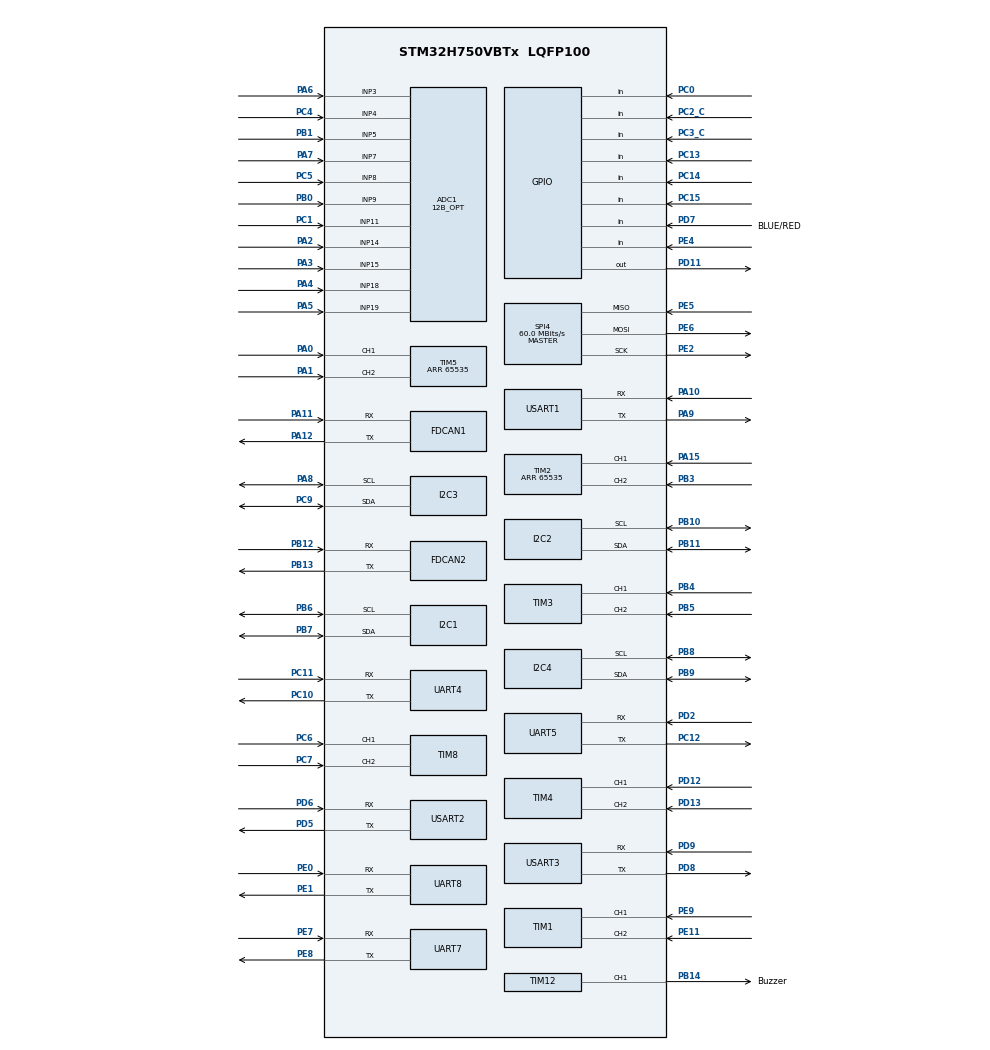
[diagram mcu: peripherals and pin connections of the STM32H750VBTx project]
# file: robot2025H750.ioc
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ADC1.Channel-0\#ChannelRegularConversion=ADC_CHANNEL_11
ADC1.Channel-1\#ChannelRegularConversion=ADC_CHANNEL_14
ADC1.Channel-10\#ChannelRegularConversion=ADC_CHANNEL_5
ADC1.Channel-2\#ChannelRegularConversion=ADC_CHANNEL_15
ADC1.Channel-3\#ChannelRegularConversion=ADC_CHANNEL_18
ADC1.Channel-4\#ChannelRegularConversion=ADC_CHANNEL_19
ADC1.Channel-5\#ChannelRegularConversion=ADC_CHANNEL_3
ADC1.Channel-6\#ChannelRegularConversion=ADC_CHANNEL_7
ADC1.Channel-7\#ChannelRegularConversion=ADC_CHANNEL_4
ADC1.Channel-8\#ChannelRegularConversion=ADC_CHANNEL_8
ADC1.Channel-9\#ChannelRegularConversion=ADC_CHANNEL_9
ADC1.ClockPrescaler=ADC_CLOCK_ASYNC_DIV4
ADC1.ContinuousConvMode=ENABLE
ADC1.ConversionDataManagement=ADC_CONVERSIONDATA_DMA_CIRCULAR
ADC1.ExternalTrigConv=ADC_SOFTWARE_START
ADC1.LowPowerAutoWait=ENABLE
ADC1.NbrOfConversion=11
ADC1.NbrOfConversionFlag=1
ADC1.OffsetNumber-0\#ChannelRegularConversion=ADC_OFFSET_NONE
ADC1.OffsetNumber-1\#ChannelRegularConversion=ADC_OFFSET_NONE
ADC1.OffsetNumber-10\#ChannelRegularConversion=ADC_OFFSET_NONE
ADC1.OffsetNumber-2\#ChannelRegularConversion=ADC_OFFSET_NONE
ADC1.OffsetNumber-3\#ChannelRegularConversion=ADC_OFFSET_NONE
ADC1.OffsetNumber-4\#ChannelRegularConversion=ADC_OFFSET_NONE
ADC1.OffsetNumber-5\#ChannelRegularConversion=ADC_OFFSET_NONE
ADC1.OffsetNumber-6\#ChannelRegularConversion=ADC_OFFSET_NONE
ADC1.OffsetNumber-7\#ChannelRegularConversion=ADC_OFFSET_NONE
ADC1.OffsetNumber-8\#ChannelRegularConversion=ADC_OFFSET_NONE
ADC1.OffsetNumber-9\#ChannelRegularConversion=ADC_OFFSET_NONE
ADC1.OffsetSignedSaturation-0\#ChannelRegularConversion=DISABLE
ADC1.OffsetSignedSaturation-1\#ChannelRegularConversion=DISABLE
ADC1.Rank-0\#ChannelRegularConversion=1
ADC1.Rank-1\#ChannelRegularConversion=2
ADC1.Rank-10\#ChannelRegularConversion=11
ADC1.Rank-2\#ChannelRegularConversion=3
ADC1.Rank-3\#ChannelRegularConversion=4
ADC1.Rank-4\#ChannelRegularConversion=5
ADC1.Rank-5\#ChannelRegularConversion=6
ADC1.Rank-6\#ChannelRegularConversion=7
ADC1.Rank-7\#ChannelRegularConversion=8
ADC1.Rank-8\#ChannelRegularConversion=9
ADC1.Rank-9\#ChannelRegularConversion=10
ADC1.Resolution=ADC_RESOLUTION_12B_OPT
ADC1.SamplingTime-0\#ChannelRegularConversion=ADC_SAMPLETIME_64CYCLES_5
ADC1.SamplingTime-1\#ChannelRegularConversion=ADC_SAMPLETIME_64CYCLES_5
ADC1.SamplingTime-10\#ChannelRegularConversion=ADC_SAMPLETIME_64CYCLES_5
ADC1.SamplingTime-2\#ChannelRegularConversion=ADC_SAMPLETIME_64CYCLES_5
ADC1.SamplingTime-3\#ChannelRegularConversion=ADC_SAMPLETIME_64CYCLES_5
ADC1.SamplingTime-4\#ChannelRegularConversion=ADC_SAMPLETIME_64CYCLES_5
ADC1.SamplingTime-5\#ChannelRegularConversion=ADC_SAMPLETIME_64CYCLES_5
ADC1.SamplingTime-6\#ChannelRegularConversion=ADC_SAMPLETIME_64CYCLES_5
ADC1.SamplingTime-7\#ChannelRegularConversion=ADC_SAMPLETIME_810CYCLES_5
ADC1.SamplingTime-8\#ChannelRegularConversion=ADC_SAMPLETIME_64CYCLES_5
ADC1.SamplingTime-9\#ChannelRegularConversion=ADC_SAMPLETIME_64CYCLES_5
ADC1.master=1
CORTEX_M7.default_mode_Activation=1
Dma.ADC1.0.Direction=DMA_PERIPH_TO_MEMORY
Dma.ADC1.0.EventEnable=DISABLE
Dma.ADC1.0.FIFOMode=DMA_FIFOMODE_DISABLE
Dma.ADC1.0.Instance=DMA1_Stream0
Dma.ADC1.0.MemDataAlignment=DMA_MDATAALIGN_HALFWORD
Dma.ADC1.0.MemInc=DMA_MINC_ENABLE
Dma.ADC1.0.Mode=DMA_CIRCULAR
Dma.ADC1.0.PeriphDataAlignment=DMA_PDATAALIGN_HALFWORD
Dma.ADC1.0.PeriphInc=DMA_PINC_DISABLE
Dma.ADC1.0.Polarity=HAL_DMAMUX_REQ_GEN_RISING
Dma.ADC1.0.Priority=DMA_PRIORITY_LOW
Dma.ADC1.0.RequestNumber=1
Dma.ADC1.0.SignalID=NONE
Dma.ADC1.0.SyncEnable=DISABLE
Dma.ADC1.0.SyncPolarity=HAL_DMAMUX_SYNC_NO_EVENT
Dma.ADC1.0.SyncRequestNumber=1
Dma.ADC1.0.SyncSignalID=NONE
Dma.Request0=ADC1
Dma.Request1=UART4_RX
Dma.Request2=USART3_RX
Dma.Request3=UART5_RX
Dma.Request4=USART1_TX
Dma.UART4_RX.1.Direction=DMA_PERIPH_TO_MEMORY
Dma.UART4_RX.1.EventEnable=DISABLE
Dma.UART4_RX.1.FIFOMode=DMA_FIFOMODE_DISABLE
Dma.UART4_RX.1.Instance=DMA1_Stream2
Dma.UART4_RX.1.MemDataAlignment=DMA_MDATAALIGN_BYTE
Dma.UART4_RX.1.MemInc=DMA_MINC_ENABLE
Dma.UART4_RX.1.Mode=DMA_CIRCULAR
Dma.UART4_RX.1.PeriphDataAlignment=DMA_PDATAALIGN_BYTE
Dma.UART4_RX.1.PeriphInc=DMA_PINC_DISABLE
Dma.UART4_RX.1.Polarity=HAL_DMAMUX_REQ_GEN_RISING
Dma.UART4_RX.1.Priority=DMA_PRIORITY_LOW
Dma.UART4_RX.1.RequestNumber=1
Dma.UART4_RX.1.SignalID=NONE
Dma.UART4_RX.1.SyncEnable=DISABLE
Dma.UART4_RX.1.SyncPolarity=HAL_DMAMUX_SYNC_NO_EVENT
Dma.UART4_RX.1.SyncRequestNumber=1
Dma.UART4_RX.1.SyncSignalID=NONE
Dma.UART5_RX.3.Direction=DMA_PERIPH_TO_MEMORY
Dma.UART5_RX.3.EventEnable=DISABLE
Dma.UART5_RX.3.FIFOMode=DMA_FIFOMODE_ENABLE
Dma.UART5_RX.3.FIFOThreshold=DMA_FIFO_THRESHOLD_HALFFULL
Dma.UART5_RX.3.Instance=DMA1_Stream4
Dma.UART5_RX.3.MemBurst=DMA_MBURST_SINGLE
Dma.UART5_RX.3.MemDataAlignment=DMA_MDATAALIGN_BYTE
Dma.UART5_RX.3.MemInc=DMA_MINC_ENABLE
Dma.UART5_RX.3.Mode=DMA_CIRCULAR
Dma.UART5_RX.3.PeriphBurst=DMA_PBURST_SINGLE
Dma.UART5_RX.3.PeriphDataAlignment=DMA_PDATAALIGN_BYTE
Dma.UART5_RX.3.PeriphInc=DMA_PINC_DISABLE
Dma.UART5_RX.3.Polarity=HAL_DMAMUX_REQ_GEN_RISING
Dma.UART5_RX.3.Priority=DMA_PRIORITY_LOW
Dma.UART5_RX.3.RequestNumber=1
Dma.UART5_RX.3.SignalID=NONE
Dma.UART5_RX.3.SyncEnable=DISABLE
Dma.UART5_RX.3.SyncPolarity=HAL_DMAMUX_SYNC_NO_EVENT
Dma.UART5_RX.3.SyncRequestNumber=1
Dma.UART5_RX.3.SyncSignalID=NONE
Dma.USART1_TX.4.Direction=DMA_MEMORY_TO_PERIPH
Dma.USART1_TX.4.EventEnable=DISABLE
Dma.USART1_TX.4.FIFOMode=DMA_FIFOMODE_ENABLE
Dma.USART1_TX.4.FIFOThreshold=DMA_FIFO_THRESHOLD_HALFFULL
Dma.USART1_TX.4.Instance=DMA1_Stream1
Dma.USART1_TX.4.MemBurst=DMA_MBURST_SINGLE
Dma.USART1_TX.4.MemDataAlignment=DMA_MDATAALIGN_BYTE
Dma.USART1_TX.4.MemInc=DMA_MINC_ENABLE
Dma.USART1_TX.4.Mode=DMA_CIRCULAR
Dma.USART1_TX.4.PeriphBurst=DMA_PBURST_SINGLE
Dma.USART1_TX.4.PeriphDataAlignment=DMA_PDATAALIGN_BYTE
Dma.USART1_TX.4.PeriphInc=DMA_PINC_DISABLE
Dma.USART1_TX.4.Polarity=HAL_DMAMUX_REQ_GEN_RISING
Dma.USART1_TX.4.Priority=DMA_PRIORITY_LOW
Dma.USART1_TX.4.RequestNumber=1
Dma.USART1_TX.4.SignalID=NONE
Dma.USART1_TX.4.SyncEnable=DISABLE
Dma.USART1_TX.4.SyncPolarity=HAL_DMAMUX_SYNC_NO_EVENT
Dma.USART1_TX.4.SyncRequestNumber=1
Dma.USART1_TX.4.SyncSignalID=NONE
Dma.USART3_RX.2.Direction=DMA_PERIPH_TO_MEMORY
Dma.USART3_RX.2.EventEnable=DISABLE
Dma.USART3_RX.2.FIFOMode=DMA_FIFOMODE_ENABLE
Dma.USART3_RX.2.FIFOThreshold=DMA_FIFO_THRESHOLD_HALFFULL
Dma.USART3_RX.2.Instance=DMA1_Stream3
Dma.USART3_RX.2.MemBurst=DMA_MBURST_SINGLE
Dma.USART3_RX.2.MemDataAlignment=DMA_MDATAALIGN_BYTE
Dma.USART3_RX.2.MemInc=DMA_MINC_ENABLE
Dma.USART3_RX.2.Mode=DMA_CIRCULAR
Dma.USART3_RX.2.PeriphBurst=DMA_PBURST_SINGLE
Dma.USART3_RX.2.PeriphDataAlignment=DMA_PDATAALIGN_BYTE
Dma.USART3_RX.2.PeriphInc=DMA_PINC_DISABLE
Dma.USART3_RX.2.Polarity=HAL_DMAMUX_REQ_GEN_RISING
Dma.USART3_RX.2.Priority=DMA_PRIORITY_LOW
Dma.USART3_RX.2.RequestNumber=1
Dma.USART3_RX.2.SignalID=NONE
Dma.USART3_RX.2.SyncEnable=DISABLE
Dma.USART3_RX.2.SyncPolarity=HAL_DMAMUX_SYNC_NO_EVENT
Dma.USART3_RX.2.SyncRequestNumber=1
Dma.USART3_RX.2.SyncSignalID=NONE
FDCAN1.CalculateBaudRateNominal=1499999
FDCAN1.CalculateTimeBitNominal=666
FDCAN1.CalculateTimeQuantumNominal=133.33333333333334
FDCAN2.CalculateBaudRateNominal=1499999
FDCAN2.CalculateTimeBitNominal=666
FDCAN2.CalculateTimeQuantumNominal=133.33333333333334
FREERTOS.Tasks01=mainTask,24,128,StartMainTask,Default,NULL,Dynamic,NULL,NULL;sensorTask02,40,128,StartSensorTask02,Default,NULL,Dynamic,NULL,NULL;swerveTask03,41,128,StartSwerveTask03,Default,NULL,Dynamic,NULL,NULL;ADCTask04,39,128,StartADCTask04,Default,NULL,Dynamic,NULL,NULL;LCDTask05,8,128,StartLCDTask05,Default,NULL,Dynamic,NULL,NULL
I2C1.Timing=0x307075B1
I2C2.Timing=0x307075B1
I2C3.Timing=0x307075B1
I2C4.Timing=0x307075B1
Mcu.Family=STM32H7
Mcu.Name=STM32H750VBTx
Mcu.Package=LQFP100
NVIC.DMA1_Stream2_IRQn=true\:5\:0\:false\:false\:true\:true\:true\:true\:true
NVIC.DMA1_Stream3_IRQn=true\:5\:0\:false\:false\:true\:true\:true\:true\:true
NVIC.DMA1_Stream4_IRQn=true\:5\:0\:false\:false\:true\:true\:true\:true\:true
NVIC.PriorityGroup=NVIC_PRIORITYGROUP_4
NVIC.TIM1_UP_IRQn=true\:5\:0\:false\:false\:true\:true\:true\:true\:true
NVIC.TIM2_IRQn=true\:5\:0\:false\:false\:true\:true\:true\:true\:true
NVIC.TIM3_IRQn=true\:5\:0\:false\:false\:true\:true\:true\:true\:true
NVIC.TIM4_IRQn=true\:5\:0\:false\:false\:true\:true\:true\:true\:true
NVIC.TIM5_IRQn=true\:5\:0\:false\:false\:true\:true\:true\:true\:true
NVIC.TIM7_IRQn=true\:15\:0\:false\:false\:true\:false\:false\:true\:true
NVIC.TIM8_UP_TIM13_IRQn=true\:5\:0\:false\:false\:true\:true\:true\:true\:true
NVIC.TimeBase=TIM7_IRQn
NVIC.TimeBaseIP=TIM7
PA0.GPIO_PuPd=GPIO_PULLUP
PA0.Signal=S_TIM5_CH1
PA1.GPIO_PuPd=GPIO_PULLUP
PA1.Signal=S_TIM5_CH2
PA10.GPIO_PuPd=GPIO_PULLUP
PA10.Mode=Asynchronous
PA10.Signal=USART1_RX
PA11.GPIO_PuPd=GPIO_PULLUP
PA11.Mode=FDCAN_Activate
PA11.Signal=FDCAN1_RX
PA12.GPIO_PuPd=GPIO_PULLUP
PA12.Mode=FDCAN_Activate
PA12.Signal=FDCAN1_TX
PA13\ (JTMS/SWDIO).Mode=Serial_Wire
PA13\ (JTMS/SWDIO).Signal=DEBUG_JTMS-SWDIO
PA14\ (JTCK/SWCLK).Mode=Serial_Wire
PA14\ (JTCK/SWCLK).Signal=DEBUG_JTCK-SWCLK
PA15\ (JTDI).GPIO_PuPd=GPIO_PULLUP
PA15\ (JTDI).Signal=S_TIM2_CH1_ETR
PA2.Signal=ADCx_INP14
PA3.Signal=ADCx_INP15
PA4.Signal=ADCx_INP18
PA5.Signal=ADCx_INP19
PA6.Signal=ADCx_INP3
PA7.Signal=ADCx_INP7
PA8.GPIO_Pu=GPIO_PULLUP
PA8.Mode=I2C
PA8.Signal=I2C3_SCL
PA9.GPIO_PuPd=GPIO_PULLUP
PA9.Mode=Asynchronous
PA9.Signal=USART1_TX
PB0.Signal=ADCx_INP9
PB1.Signal=ADCx_INP5
PB10.GPIO_Pu=GPIO_PULLUP
PB10.Mode=I2C
PB10.Signal=I2C2_SCL
PB11.GPIO_Pu=GPIO_PULLUP
PB11.Mode=I2C
PB11.Signal=I2C2_SDA
PB12.GPIO_PuPd=GPIO_PULLUP
PB12.Mode=FDCAN_Activate
PB12.Signal=FDCAN2_RX
PB13.GPIO_PuPd=GPIO_PULLUP
PB13.Mode=FDCAN_Activate
PB13.Signal=FDCAN2_TX
PB14.GPIO_Label=Buzzer
PB14.Signal=S_TIM12_CH1
PB3\ (JTDO/TRACESWO).GPIO_PuPd=GPIO_PULLUP
PB3\ (JTDO/TRACESWO).Signal=S_TIM2_CH2
PB4\ (NJTRST).GPIO_PuPd=GPIO_PULLUP
PB4\ (NJTRST).Signal=S_TIM3_CH1
PB5.GPIO_PuPd=GPIO_PULLUP
PB5.Signal=S_TIM3_CH2
PB6.GPIO_Pu=GPIO_PULLUP
PB6.Mode=I2C
PB6.Signal=I2C1_SCL
PB7.GPIO_Pu=GPIO_PULLUP
PB7.Mode=I2C
PB7.Signal=I2C1_SDA
PB8.GPIO_Pu=GPIO_PULLUP
PB8.Mode=I2C
PB8.Signal=I2C4_SCL
PB9.GPIO_Pu=GPIO_PULLUP
PB9.Mode=I2C
PB9.Signal=I2C4_SDA
PC0.Signal=GPIO_Input
PC1.Signal=ADCx_INP11
PC10.GPIO_PuPd=GPIO_PULLUP
PC10.Mode=Asynchronous
PC10.Signal=UART4_TX
PC11.GPIO_PuPd=GPIO_PULLUP
PC11.Mode=Asynchronous
PC11.Signal=UART4_RX
PC12.GPIO_PuPd=GPIO_PULLUP
PC12.Mode=Asynchronous
PC12.Signal=UART5_TX
PC13.Signal=GPIO_Input
PC14-OSC32_IN\ (OSC32_IN).Signal=GPIO_Input
PC15-OSC32_OUT\ (OSC32_OUT).Signal=GPIO_Input
PC2_C.Signal=GPIO_Input
PC3_C.Signal=GPIO_Input
PC4.Signal=ADCx_INP4
PC5.Signal=ADCx_INP8
PC6.Signal=S_TIM8_CH1
PC7.Signal=S_TIM8_CH2
PC9.GPIO_Pu=GPIO_PULLUP
PC9.Mode=I2C
PC9.Signal=I2C3_SDA
PD11.Signal=GPIO_Output
PD12.GPIO_PuPd=GPIO_PULLUP
PD12.Signal=S_TIM4_CH1
PD13.GPIO_PuPd=GPIO_PULLUP
PD13.Signal=S_TIM4_CH2
PD2.GPIO_PuPd=GPIO_PULLUP
PD2.Mode=Asynchronous
PD2.Signal=UART5_RX
PD5.GPIO_PuPd=GPIO_PULLUP
PD5.Mode=Asynchronous
PD5.Signal=USART2_TX
PD6.GPIO_PuPd=GPIO_PULLUP
PD6.Mode=Asynchronous
PD6.Signal=USART2_RX
PD7.GPIO_Label=BLUE/RED
PD7.Signal=GPIO_Input
PD8.GPIO_PuPd=GPIO_PULLUP
PD8.Mode=Asynchronous
PD8.Signal=USART3_TX
PD9.GPIO_PuPd=GPIO_PULLUP
PD9.Mode=Asynchronous
PD9.Signal=USART3_RX
PE0.GPIO_PuPd=GPIO_PULLUP
PE0.Mode=Asynchronous
PE0.Signal=UART8_RX
PE1.GPIO_PuPd=GPIO_PULLUP
PE1.Mode=Asynchronous
PE1.Signal=UART8_TX
PE11.GPIO_PuPd=GPIO_PULLUP
PE11.Signal=S_TIM1_CH2
PE2.Mode=Full_Duplex_Master
PE2.Signal=SPI4_SCK
PE4.Signal=GPIO_Input
PE5.Mode=Full_Duplex_Master
PE5.Signal=SPI4_MISO
PE6.Mode=Full_Duplex_Master
PE6.Signal=SPI4_MOSI
PE7.GPIO_PuPd=GPIO_PULLUP
PE7.Mode=Asynchronous
PE7.Signal=UART7_RX
PE8.GPIO_PuPd=GPIO_PULLUP
PE8.Mode=Asynchronous
PE8.Signal=UART7_TX
PE9.GPIO_PuPd=GPIO_PULLUP
PE9.Signal=S_TIM1_CH1
PH0-OSC_IN\ (PH0).Mode=HSE-External-Oscillator
PH0-OSC_IN\ (PH0).Signal=RCC_OSC_IN
PH1-OSC_OUT\ (PH1).Mode=HSE-External-Oscillator
PH1-OSC_OUT\ (PH1).Signal=RCC_OSC_OUT
ProjectManager.HeapSize=0x200
ProjectManager.StackSize=0x400
ProjectManager.TargetToolchain=MDK-ARM V5.32
RCC.ADCFreq_Value=75000000
RCC.APB1Freq_Value=120000000
RCC.APB2Freq_Value=120000000
RCC.APB3Freq_Value=120000000
RCC.APB4Freq_Value=120000000
RCC.CortexFreq_Value=480000000
RCC.D1PPRE=RCC_APB3_DIV2
RCC.D2PPRE1=RCC_APB1_DIV2
RCC.D2PPRE2=RCC_APB2_DIV2
RCC.D3PPRE=RCC_APB4_DIV2
RCC.DIVM1=5
RCC.DIVM2=25
RCC.DIVM3=25
RCC.DIVN1=192
RCC.DIVN2=150
RCC.DIVN3=50
RCC.DIVQ1=8
RCC.FLatency-AdvancedSettings=FLASH_LATENCY_0
RCC.HCLKFreq_Value=240000000
RCC.HPRE=RCC_HCLK_DIV2
RCC.HSE_VALUE=25000000
RCC.PLL2_VCI_Range-AdvancedSettings=RCC_PLL2VCIRANGE_1
RCC.PLL2_VCO_SEL-AdvancedSettings=RCC_PLL2VCOWIDE
RCC.PLL3_VCI_Range-AdvancedSettings=RCC_PLL3VCIRANGE_3
RCC.PLLSourceVirtual=RCC_PLLSOURCE_HSE
RCC.SYSCLKFreq_VALUE=480000000
RCC.SYSCLKSource=RCC_SYSCLKSOURCE_PLLCLK
RCC.USBFreq_Value=120000000
SH.ADCx_INP11.0=ADC1_INP11,IN11-Single-Ended
SH.ADCx_INP14.0=ADC1_INP14,IN14-Single-Ended
SH.ADCx_INP15.0=ADC1_INP15,IN15-Single-Ended
SH.ADCx_INP18.0=ADC1_INP18,IN18-Single-Ended
SH.ADCx_INP19.0=ADC1_INP19,IN19-Single-Ended
SH.ADCx_INP3.0=ADC1_INP3,IN3-Single-Ended
SH.ADCx_INP4.0=ADC1_INP4,IN4-Single-Ended
SH.ADCx_INP5.0=ADC1_INP5,IN5-Single-Ended
SH.ADCx_INP7.0=ADC1_INP7,IN7-Single-Ended
SH.ADCx_INP8.0=ADC1_INP8,IN8-Single-Ended
SH.ADCx_INP9.0=ADC1_INP9,IN9-Single-Ended
SH.S_TIM12_CH1.0=TIM12_CH1,PWM Generation1 CH1
SH.S_TIM1_CH1.0=TIM1_CH1,Encoder_Interface
SH.S_TIM1_CH2.0=TIM1_CH2,Encoder_Interface
SH.S_TIM2_CH1_ETR.0=TIM2_CH1,Encoder_Interface
SH.S_TIM2_CH2.0=TIM2_CH2,Encoder_Interface
SH.S_TIM3_CH1.0=TIM3_CH1,Encoder_Interface
SH.S_TIM3_CH2.0=TIM3_CH2,Encoder_Interface
SH.S_TIM4_CH1.0=TIM4_CH1,Encoder_Interface
SH.S_TIM4_CH2.0=TIM4_CH2,Encoder_Interface
SH.S_TIM5_CH1.0=TIM5_CH1,Encoder_Interface
SH.S_TIM5_CH2.0=TIM5_CH2,Encoder_Interface
SH.S_TIM8_CH1.0=TIM8_CH1,Encoder_Interface
SH.S_TIM8_CH2.0=TIM8_CH2,Encoder_Interface
SPI4.CalculateBaudRate=60.0 MBits/s
SPI4.Direction=SPI_DIRECTION_2LINES
SPI4.Mode=SPI_MODE_MASTER
SPI4.VirtualType=VM_MASTER
TIM1.ClockDivision=TIM_CLOCKDIVISION_DIV4
TIM1.CounterMode=TIM_COUNTERMODE_DOWN
TIM1.EncoderMode=TIM_ENCODERMODE_TI12
TIM1.IC1Polarity=TIM_ICPOLARITY_FALLING
TIM1.IC2Polarity=TIM_ICPOLARITY_FALLING
TIM12.Channel-PWM\ Generation1\ CH1=TIM_CHANNEL_1
TIM2.ClockDivision=TIM_CLOCKDIVISION_DIV4
TIM2.CounterMode=TIM_COUNTERMODE_DOWN
TIM2.EncoderMode=TIM_ENCODERMODE_TI12
TIM2.IC1Polarity=TIM_ICPOLARITY_FALLING
TIM2.IC2Polarity=TIM_ICPOLARITY_FALLING
TIM2.Period=65535
TIM3.ClockDivision=TIM_CLOCKDIVISION_DIV4
TIM3.CounterMode=TIM_COUNTERMODE_DOWN
TIM3.EncoderMode=TIM_ENCODERMODE_TI12
TIM3.IC1Polarity=TIM_ICPOLARITY_FALLING
TIM3.IC2Polarity=TIM_ICPOLARITY_FALLING
TIM4.ClockDivision=TIM_CLOCKDIVISION_DIV4
TIM4.CounterMode=TIM_COUNTERMODE_DOWN
TIM4.EncoderMode=TIM_ENCODERMODE_TI12
TIM4.IC1Polarity=TIM_ICPOLARITY_FALLING
TIM4.IC1Prescaler=TIM_ICPSC_DIV1
TIM4.IC2Polarity=TIM_ICPOLARITY_FALLING
TIM4.IC2Prescaler=TIM_ICPSC_DIV1
TIM5.ClockDivision=TIM_CLOCKDIVISION_DIV4
TIM5.CounterMode=TIM_COUNTERMODE_DOWN
TIM5.EncoderMode=TIM_ENCODERMODE_TI12
TIM5.IC1Polarity=TIM_ICPOLARITY_FALLING
TIM5.IC2Polarity=TIM_ICPOLARITY_FALLING
TIM5.Period=65535
TIM8.ClockDivision=TIM_CLOCKDIVISION_DIV4
TIM8.CounterMode=TIM_COUNTERMODE_DOWN
TIM8.EncoderMode=TIM_ENCODERMODE_TI12
TIM8.IC1Polarity=TIM_ICPOLARITY_FALLING
TIM8.IC2Polarity=TIM_ICPOLARITY_FALLING
USART1.VirtualMode-Asynchronous=VM_ASYNC
USART2.VirtualMode-Asynchronous=VM_ASYNC
USART3.VirtualMode-Asynchronous=VM_ASYNC
VP_FREERTOS_VS_CMSIS_V2.Mode=CMSIS_V2
VP_MEMORYMAP_VS_MEMORYMAP.Mode=CurAppReg
VP_SYS_VS_tim7.Mode=TIM7
board=custom

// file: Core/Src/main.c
/* USER CODE BEGIN Header */
/**
  ******************************************************************************
  * @file           : main.c
  * @brief          : Main program body
  ******************************************************************************
  * @attention
  *
  * Copyright (c) 2024 STMicroelectronics.
  * All rights reserved.
  *
  * This software is licensed under terms that can be found in the LICENSE file
  * in the root directory of this software component.
  * If no LICENSE file comes with this software, it is provided AS-IS.
  *
  ******************************************************************************
  */
/* USER CODE END Header */
#include "main.h"
#include "cmsis_os.h"

/* USER CODE BEGIN Includes */
#include "i2c_lcd.h"
#include "ala_Config.h"
#include "BasicFunction.h"
#include "gamepad_bluetooth.h"
#include "LCD_Shows.h"
#include "3SwerveWheel.h"
/* USER CODE END Includes */

/* USER CODE BEGIN PTD */
extern CLCD_I2C_Name LCD1;
/* USER CODE END PTD */

/* USER CODE BEGIN PD */
uint8_t RX_UART1[2], RX_UART2[15], RX_UART3[1], RX_UART4[10], RX_UART5[11];
/* USER CODE END PD */

/* USER CODE BEGIN PM */
int bienTestPid = 0;
int16_t IMU, IMU_china; // bien chua data Gyro
uint8_t modeLCD_Show = 0;
uint16_t adc_data[11];
int demaa = 0;
float mainBoardPower = 0.0;
/* USER CODE END PM */

ADC_HandleTypeDef hadc1;
DMA_HandleTypeDef hdma_adc1;

FDCAN_HandleTypeDef hfdcan1;
FDCAN_HandleTypeDef hfdcan2;

I2C_HandleTypeDef hi2c1;
I2C_HandleTypeDef hi2c2;
I2C_HandleTypeDef hi2c3;
I2C_HandleTypeDef hi2c4;

SPI_HandleTypeDef hspi4;

TIM_HandleTypeDef htim1;
TIM_HandleTypeDef htim2;
TIM_HandleTypeDef htim3;
TIM_HandleTypeDef htim4;
TIM_HandleTypeDef htim5;
TIM_HandleTypeDef htim8;
TIM_HandleTypeDef htim12;

UART_HandleTypeDef huart4;
UART_HandleTypeDef huart5;
UART_HandleTypeDef huart7;
UART_HandleTypeDef huart8;
UART_HandleTypeDef huart1;
UART_HandleTypeDef huart2;
UART_HandleTypeDef huart3;
DMA_HandleTypeDef hdma_uart4_rx;
DMA_HandleTypeDef hdma_uart5_rx;
DMA_HandleTypeDef hdma_usart1_tx;
DMA_HandleTypeDef hdma_usart3_rx;

/* Definitions for mainTask */
osThreadId_t mainTaskHandle;
const osThreadAttr_t mainTask_attributes = {
  .name = "mainTask",
  .stack_size = 128 * 4,
  .priority = (osPriority_t) osPriorityNormal,
};
/* Definitions for sensorTask02 */
osThreadId_t sensorTask02Handle;
const osThreadAttr_t sensorTask02_attributes = {
  .name = "sensorTask02",
  .stack_size = 128 * 4,
  .priority = (osPriority_t) osPriorityHigh,
};
/* Definitions for swerveTask03 */
osThreadId_t swerveTask03Handle;
const osThreadAttr_t swerveTask03_attributes = {
  .name = "swerveTask03",
  .stack_size = 128 * 4,
  .priority = (osPriority_t) osPriorityHigh1,
};
/* Definitions for ADCTask04 */
osThreadId_t ADCTask04Handle;
const osThreadAttr_t ADCTask04_attributes = {
  .name = "ADCTask04",
  .stack_size = 128 * 4,
  .priority = (osPriority_t) osPriorityAboveNormal7,
};
/* Definitions for LCDTask05 */
osThreadId_t LCDTask05Handle;
const osThreadAttr_t LCDTask05_attributes = {
  .name = "LCDTask05",
  .stack_size = 128 * 4,
  .priority = (osPriority_t) osPriorityLow,
};

void SystemClock_Config(void);
static void MPU_Config(void);
static void MX_GPIO_Init(void);
static void MX_DMA_Init(void);
static void MX_I2C1_Init(void);
static void MX_I2C2_Init(void);
static void MX_I2C3_Init(void);
static void MX_I2C4_Init(void);
static void MX_TIM1_Init(void);
static void MX_TIM2_Init(void);
static void MX_TIM3_Init(void);
static void MX_TIM4_Init(void);
static void MX_TIM5_Init(void);
static void MX_TIM8_Init(void);
static void MX_FDCAN1_Init(void);
static void MX_FDCAN2_Init(void);
static void MX_SPI4_Init(void);
static void MX_UART4_Init(void);
static void MX_UART5_Init(void);
static void MX_UART7_Init(void);
static void MX_UART8_Init(void);
static void MX_USART1_UART_Init(void);
static void MX_USART2_UART_Init(void);
static void MX_USART3_UART_Init(void);
static void MX_ADC1_Init(void);
static void MX_TIM12_Init(void);
void StartMainTask(void *argument);
void StartSensorTask02(void *argument);
void StartSwerveTask03(void *argument);
void StartADCTask04(void *argument);
void StartLCDTask05(void *argument);

int main(void)
{

  /* MPU Configuration--------------------------------------------------------*/
  MPU_Config();

  /* MCU Configuration--------------------------------------------------------*/

  /* Reset of all peripherals, Initializes the Flash interface and the Systick. */
  HAL_Init();

  /* Configure the system clock */
  SystemClock_Config();

  /* Initialize all configured peripherals */
  MX_GPIO_Init();
  MX_DMA_Init();
  MX_I2C1_Init();
  MX_I2C2_Init();
  MX_I2C3_Init();
  MX_I2C4_Init();
  MX_TIM1_Init();
  MX_TIM2_Init();
  MX_TIM3_Init();
  MX_TIM4_Init();
  MX_TIM5_Init();
  MX_TIM8_Init();
  MX_FDCAN1_Init();
  MX_FDCAN2_Init();
  MX_SPI4_Init();
  MX_UART4_Init();
  MX_UART5_Init();
  MX_UART7_Init();
  MX_UART8_Init();
  MX_USART1_UART_Init();
  MX_USART2_UART_Init();
  MX_USART3_UART_Init();
  MX_ADC1_Init();
  MX_TIM12_Init();
  /* USER CODE BEGIN 2 */

	//HAL_UART_Transmit_DMA(&huart1, motorData, sizeof(motorData));		// Mo DMA giao tiep Driver

	HAL_ADC_Start_DMA(&hadc1,(uint32_t*)&adc_data,11); // cho phep khoi chay DMA ADC
	// Timer Encoder
	HAL_TIM_Base_Start_IT(&htim1);
	HAL_TIM_Encoder_Start(&htim1, TIM_CHANNEL_ALL);	// mo mode encoder tim 1
	HAL_TIM_Base_Start_IT(&htim2);
	HAL_TIM_Encoder_Start(&htim2, TIM_CHANNEL_ALL);	// mo mode encoder tim 2
	HAL_TIM_Base_Start_IT(&htim3);
	HAL_TIM_Encoder_Start(&htim3, TIM_CHANNEL_ALL);	// mo mode encoder tim 3
	HAL_TIM_Base_Start_IT(&htim4);
	HAL_TIM_Encoder_Start(&htim4, TIM_CHANNEL_ALL);	// mo mode encoder tim 4
	HAL_TIM_Base_Start_IT(&htim5);
	HAL_TIM_Encoder_Start(&htim5, TIM_CHANNEL_ALL);	// mo mode encoder tim 5
	HAL_TIM_Base_Start_IT(&htim8);
	HAL_TIM_Encoder_Start(&htim8, TIM_CHANNEL_ALL);	// mo mode encoder tim 8

	//----------------------------- Enable UART 4 --------------------------------------
	HAL_UART_Receive_DMA(&huart4, RX_UART4, 10);		// Ket noi Laban Gyro
	HAL_UART_Receive_DMA(&huart3, MANG_GAME, 8);		// Khai bao cap nhat mang cho gamePad
	HAL_UART_Receive_DMA(&huart5, RX_UART5, 11);		// Ket noi Laban TQ

	//mor_4h = 3;
	//motorData[11] = 20;
//	while(1){
//		if(robotAngle_TQ() == 0) break;
//		resetIMU_TQ();
//		HAL_Delay(10);
//	}
  /* USER CODE END 2 */

  /* Init scheduler */
  osKernelInitialize();

  /* Create the thread(s) */
  /* creation of mainTask */
  mainTaskHandle = osThreadNew(StartMainTask, NULL, &mainTask_attributes);

  /* creation of sensorTask02 */
  sensorTask02Handle = osThreadNew(StartSensorTask02, NULL, &sensorTask02_attributes);

  /* creation of swerveTask03 */
  swerveTask03Handle = osThreadNew(StartSwerveTask03, NULL, &swerveTask03_attributes);

  /* creation of ADCTask04 */
  ADCTask04Handle = osThreadNew(StartADCTask04, NULL, &ADCTask04_attributes);

  /* creation of LCDTask05 */
  LCDTask05Handle = osThreadNew(StartLCDTask05, NULL, &LCDTask05_attributes);

  /* Start scheduler */
  osKernelStart();

  /* We should never get here as control is now taken by the scheduler */

  /* Infinite loop */
  while (1)
  {

  }
}

void SystemClock_Config(void)
{
  RCC_OscInitTypeDef RCC_OscInitStruct = {0};
  RCC_ClkInitTypeDef RCC_ClkInitStruct = {0};

  /** Supply configuration update enable
  */
  HAL_PWREx_ConfigSupply(PWR_LDO_SUPPLY);

  /** Configure the main internal regulator output voltage
  */
  __HAL_PWR_VOLTAGESCALING_CONFIG(PWR_REGULATOR_VOLTAGE_SCALE1);

  while(!__HAL_PWR_GET_FLAG(PWR_FLAG_VOSRDY)) {}

  __HAL_RCC_SYSCFG_CLK_ENABLE();
  __HAL_PWR_VOLTAGESCALING_CONFIG(PWR_REGULATOR_VOLTAGE_SCALE0);

  while(!__HAL_PWR_GET_FLAG(PWR_FLAG_VOSRDY)) {}

  /** Initializes the RCC Oscillators according to the specified parameters
  * in the RCC_OscInitTypeDef structure.
  */
  RCC_OscInitStruct.OscillatorType = RCC_OSCILLATORTYPE_HSE;
  RCC_OscInitStruct.HSEState = RCC_HSE_ON;
  RCC_OscInitStruct.PLL.PLLState = RCC_PLL_ON;
  RCC_OscInitStruct.PLL.PLLSource = RCC_PLLSOURCE_HSE;
  RCC_OscInitStruct.PLL.PLLM = 5;
  RCC_OscInitStruct.PLL.PLLN = 192;
  RCC_OscInitStruct.PLL.PLLP = 2;
  RCC_OscInitStruct.PLL.PLLQ = 8;
  RCC_OscInitStruct.PLL.PLLR = 2;
  RCC_OscInitStruct.PLL.PLLRGE = RCC_PLL1VCIRANGE_2;
  RCC_OscInitStruct.PLL.PLLVCOSEL = RCC_PLL1VCOWIDE;
  RCC_OscInitStruct.PLL.PLLFRACN = 0;
  if (HAL_RCC_OscConfig(&RCC_OscInitStruct) != HAL_OK)
  {
    Error_Handler();
  }

  /** Initializes the CPU, AHB and APB buses clocks
  */
  RCC_ClkInitStruct.ClockType = RCC_CLOCKTYPE_HCLK|RCC_CLOCKTYPE_SYSCLK
                              |RCC_CLOCKTYPE_PCLK1|RCC_CLOCKTYPE_PCLK2
                              |RCC_CLOCKTYPE_D3PCLK1|RCC_CLOCKTYPE_D1PCLK1;
  RCC_ClkInitStruct.SYSCLKSource = RCC_SYSCLKSOURCE_PLLCLK;
  RCC_ClkInitStruct.SYSCLKDivider = RCC_SYSCLK_DIV1;
  RCC_ClkInitStruct.AHBCLKDivider = RCC_HCLK_DIV2;
  RCC_ClkInitStruct.APB3CLKDivider = RCC_APB3_DIV2;
  RCC_ClkInitStruct.APB1CLKDivider = RCC_APB1_DIV2;
  RCC_ClkInitStruct.APB2CLKDivider = RCC_APB2_DIV2;
  RCC_ClkInitStruct.APB4CLKDivider = RCC_APB4_DIV2;

  if (HAL_RCC_ClockConfig(&RCC_ClkInitStruct, FLASH_LATENCY_4) != HAL_OK)
  {
    Error_Handler();
  }
}

static void MX_ADC1_Init(void)
{

  ADC_MultiModeTypeDef multimode = {0};
  ADC_ChannelConfTypeDef sConfig = {0};

  /** Common config
  */
  hadc1.Instance = ADC1;
  hadc1.Init.ScanConvMode = ADC_SCAN_ENABLE;
  hadc1.Init.EOCSelection = ADC_EOC_SINGLE_CONV;
  hadc1.Init.LowPowerAutoWait = ENABLE;
  hadc1.Init.ContinuousConvMode = ENABLE;
  hadc1.Init.NbrOfConversion = 11;
  hadc1.Init.DiscontinuousConvMode = DISABLE;
  hadc1.Init.ExternalTrigConv = ADC_SOFTWARE_START;
  hadc1.Init.ExternalTrigConvEdge = ADC_EXTERNALTRIGCONVEDGE_NONE;
  hadc1.Init.ConversionDataManagement = ADC_CONVERSIONDATA_DMA_CIRCULAR;
  hadc1.Init.Overrun = ADC_OVR_DATA_PRESERVED;
  hadc1.Init.LeftBitShift = ADC_LEFTBITSHIFT_NONE;
  hadc1.Init.OversamplingMode = DISABLE;
  hadc1.Init.Oversampling.Ratio = 1;
  if (HAL_ADC_Init(&hadc1) != HAL_OK)
  {
    Error_Handler();
  }
  hadc1.Init.ClockPrescaler = ADC_CLOCK_ASYNC_DIV4;
  hadc1.Init.Resolution = ADC_RESOLUTION_12B_OPT;
  if (HAL_ADC_Init(&hadc1) != HAL_OK)
  {
    Error_Handler();
  }

  /** Configure the ADC multi-mode
  */
  multimode.Mode = ADC_MODE_INDEPENDENT;
  if (HAL_ADCEx_MultiModeConfigChannel(&hadc1, &multimode) != HAL_OK)
  {
    Error_Handler();
  }

  /** Configure Regular Channel
  */
  sConfig.Channel = ADC_CHANNEL_11;
  sConfig.Rank = ADC_REGULAR_RANK_1;
  sConfig.SamplingTime = ADC_SAMPLETIME_64CYCLES_5;
  sConfig.SingleDiff = ADC_SINGLE_ENDED;
  sConfig.OffsetNumber = ADC_OFFSET_NONE;
  sConfig.Offset = 0;
  sConfig.OffsetSignedSaturation = DISABLE;
  if (HAL_ADC_ConfigChannel(&hadc1, &sConfig) != HAL_OK)
  {
    Error_Handler();
  }

  /** Configure Regular Channel
  */
  sConfig.Channel = ADC_CHANNEL_14;
  sConfig.Rank = ADC_REGULAR_RANK_2;
  if (HAL_ADC_ConfigChannel(&hadc1, &sConfig) != HAL_OK)
  {
    Error_Handler();
  }

  /** Configure Regular Channel
  */
  sConfig.Channel = ADC_CHANNEL_15;
  sConfig.Rank = ADC_REGULAR_RANK_3;
  if (HAL_ADC_ConfigChannel(&hadc1, &sConfig) != HAL_OK)
  {
    Error_Handler();
  }

  /** Configure Regular Channel
  */
  sConfig.Channel = ADC_CHANNEL_18;
  sConfig.Rank = ADC_REGULAR_RANK_4;
  if (HAL_ADC_ConfigChannel(&hadc1, &sConfig) != HAL_OK)
  {
    Error_Handler();
  }

  /** Configure Regular Channel
  */
  sConfig.Channel = ADC_CHANNEL_19;
  sConfig.Rank = ADC_REGULAR_RANK_5;
  if (HAL_ADC_ConfigChannel(&hadc1, &sConfig) != HAL_OK)
  {
    Error_Handler();
  }

  /** Configure Regular Channel
  */
  sConfig.Channel = ADC_CHANNEL_3;
  sConfig.Rank = ADC_REGULAR_RANK_6;
  if (HAL_ADC_ConfigChannel(&hadc1, &sConfig) != HAL_OK)
  {
    Error_Handler();
  }

  /** Configure Regular Channel
  */
  sConfig.Channel = ADC_CHANNEL_7;
  sConfig.Rank = ADC_REGULAR_RANK_7;
  if (HAL_ADC_ConfigChannel(&hadc1, &sConfig) != HAL_OK)
  {
    Error_Handler();
  }

  /** Configure Regular Channel
  */
  sConfig.Channel = ADC_CHANNEL_4;
  sConfig.Rank = ADC_REGULAR_RANK_8;
  sConfig.SamplingTime = ADC_SAMPLETIME_810CYCLES_5;
  if (HAL_ADC_ConfigChannel(&hadc1, &sConfig) != HAL_OK)
  {
    Error_Handler();
  }

  /** Configure Regular Channel
  */
  sConfig.Channel = ADC_CHANNEL_8;
  sConfig.Rank = ADC_REGULAR_RANK_9;
  sConfig.SamplingTime = ADC_SAMPLETIME_64CYCLES_5;
  if (HAL_ADC_ConfigChannel(&hadc1, &sConfig) != HAL_OK)
  {
    Error_Handler();
  }

  /** Configure Regular Channel
  */
  sConfig.Channel = ADC_CHANNEL_9;
  sConfig.Rank = ADC_REGULAR_RANK_10;
  if (HAL_ADC_ConfigChannel(&hadc1, &sConfig) != HAL_OK)
  {
    Error_Handler();
  }

  /** Configure Regular Channel
  */
  sConfig.Channel = ADC_CHANNEL_5;
  sConfig.Rank = ADC_REGULAR_RANK_11;
  if (HAL_ADC_ConfigChannel(&hadc1, &sConfig) != HAL_OK)
  {
    Error_Handler();
  }

}

static void MX_FDCAN1_Init(void)
{

  hfdcan1.Instance = FDCAN1;
  hfdcan1.Init.FrameFormat = FDCAN_FRAME_CLASSIC;
  hfdcan1.Init.Mode = FDCAN_MODE_NORMAL;
  hfdcan1.Init.AutoRetransmission = DISABLE;
  hfdcan1.Init.TransmitPause = DISABLE;
  hfdcan1.Init.ProtocolException = DISABLE;
  hfdcan1.Init.NominalPrescaler = 16;
  hfdcan1.Init.NominalSyncJumpWidth = 1;
  hfdcan1.Init.NominalTimeSeg1 = 2;
  hfdcan1.Init.NominalTimeSeg2 = 2;
  hfdcan1.Init.DataPrescaler = 1;
  hfdcan1.Init.DataSyncJumpWidth = 1;
  hfdcan1.Init.DataTimeSeg1 = 1;
  hfdcan1.Init.DataTimeSeg2 = 1;
  hfdcan1.Init.MessageRAMOffset = 0;
  hfdcan1.Init.StdFiltersNbr = 0;
  hfdcan1.Init.ExtFiltersNbr = 0;
  hfdcan1.Init.RxFifo0ElmtsNbr = 0;
  hfdcan1.Init.RxFifo0ElmtSize = FDCAN_DATA_BYTES_8;
  hfdcan1.Init.RxFifo1ElmtsNbr = 0;
  hfdcan1.Init.RxFifo1ElmtSize = FDCAN_DATA_BYTES_8;
  hfdcan1.Init.RxBuffersNbr = 0;
  hfdcan1.Init.RxBufferSize = FDCAN_DATA_BYTES_8;
  hfdcan1.Init.TxEventsNbr = 0;
  hfdcan1.Init.TxBuffersNbr = 0;
  hfdcan1.Init.TxFifoQueueElmtsNbr = 0;
  hfdcan1.Init.TxFifoQueueMode = FDCAN_TX_FIFO_OPERATION;
  hfdcan1.Init.TxElmtSize = FDCAN_DATA_BYTES_8;
  if (HAL_FDCAN_Init(&hfdcan1) != HAL_OK)
  {
    Error_Handler();
  }

}

static void MX_FDCAN2_Init(void)
{

  hfdcan2.Instance = FDCAN2;
  hfdcan2.Init.FrameFormat = FDCAN_FRAME_CLASSIC;
  hfdcan2.Init.Mode = FDCAN_MODE_NORMAL;
  hfdcan2.Init.AutoRetransmission = DISABLE;
  hfdcan2.Init.TransmitPause = DISABLE;
  hfdcan2.Init.ProtocolException = DISABLE;
  hfdcan2.Init.NominalPrescaler = 16;
  hfdcan2.Init.NominalSyncJumpWidth = 1;
  hfdcan2.Init.NominalTimeSeg1 = 2;
  hfdcan2.Init.NominalTimeSeg2 = 2;
  hfdcan2.Init.DataPrescaler = 1;
  hfdcan2.Init.DataSyncJumpWidth = 1;
  hfdcan2.Init.DataTimeSeg1 = 1;
  hfdcan2.Init.DataTimeSeg2 = 1;
  hfdcan2.Init.MessageRAMOffset = 0;
  hfdcan2.Init.StdFiltersNbr = 0;
  hfdcan2.Init.ExtFiltersNbr = 0;
  hfdcan2.Init.RxFifo0ElmtsNbr = 0;
  hfdcan2.Init.RxFifo0ElmtSize = FDCAN_DATA_BYTES_8;
  hfdcan2.Init.RxFifo1ElmtsNbr = 0;
  hfdcan2.Init.RxFifo1ElmtSize = FDCAN_DATA_BYTES_8;
  hfdcan2.Init.RxBuffersNbr = 0;
  hfdcan2.Init.RxBufferSize = FDCAN_DATA_BYTES_8;
  hfdcan2.Init.TxEventsNbr = 0;
  hfdcan2.Init.TxBuffersNbr = 0;
  hfdcan2.Init.TxFifoQueueElmtsNbr = 0;
  hfdcan2.Init.TxFifoQueueMode = FDCAN_TX_FIFO_OPERATION;
  hfdcan2.Init.TxElmtSize = FDCAN_DATA_BYTES_8;
  if (HAL_FDCAN_Init(&hfdcan2) != HAL_OK)
  {
    Error_Handler();
  }

}

static void MX_I2C1_Init(void)
{

  hi2c1.Instance = I2C1;
  hi2c1.Init.Timing = 0x307075B1;
  hi2c1.Init.OwnAddress1 = 0;
  hi2c1.Init.AddressingMode = I2C_ADDRESSINGMODE_7BIT;
  hi2c1.Init.DualAddressMode = I2C_DUALADDRESS_DISABLE;
  hi2c1.Init.OwnAddress2 = 0;
  hi2c1.Init.OwnAddress2Masks = I2C_OA2_NOMASK;
  hi2c1.Init.GeneralCallMode = I2C_GENERALCALL_DISABLE;
  hi2c1.Init.NoStretchMode = I2C_NOSTRETCH_DISABLE;
  if (HAL_I2C_Init(&hi2c1) != HAL_OK)
  {
    Error_Handler();
  }

  /** Configure Analogue filter
  */
  if (HAL_I2CEx_ConfigAnalogFilter(&hi2c1, I2C_ANALOGFILTER_ENABLE) != HAL_OK)
  {
    Error_Handler();
  }

  /** Configure Digital filter
  */
  if (HAL_I2CEx_ConfigDigitalFilter(&hi2c1, 0) != HAL_OK)
  {
    Error_Handler();
  }

}

static void MX_I2C2_Init(void)
{

  hi2c2.Instance = I2C2;
  hi2c2.Init.Timing = 0x307075B1;
  hi2c2.Init.OwnAddress1 = 0;
  hi2c2.Init.AddressingMode = I2C_ADDRESSINGMODE_7BIT;
  hi2c2.Init.DualAddressMode = I2C_DUALADDRESS_DISABLE;
  hi2c2.Init.OwnAddress2 = 0;
  hi2c2.Init.OwnAddress2Masks = I2C_OA2_NOMASK;
  hi2c2.Init.GeneralCallMode = I2C_GENERALCALL_DISABLE;
  hi2c2.Init.NoStretchMode = I2C_NOSTRETCH_DISABLE;
  if (HAL_I2C_Init(&hi2c2) != HAL_OK)
  {
    Error_Handler();
  }

  /** Configure Analogue filter
  */
  if (HAL_I2CEx_ConfigAnalogFilter(&hi2c2, I2C_ANALOGFILTER_ENABLE) != HAL_OK)
  {
    Error_Handler();
  }

  /** Configure Digital filter
  */
  if (HAL_I2CEx_ConfigDigitalFilter(&hi2c2, 0) != HAL_OK)
  {
    Error_Handler();
  }

}

static void MX_I2C3_Init(void)
{

  hi2c3.Instance = I2C3;
  hi2c3.Init.Timing = 0x307075B1;
  hi2c3.Init.OwnAddress1 = 0;
  hi2c3.Init.AddressingMode = I2C_ADDRESSINGMODE_7BIT;
  hi2c3.Init.DualAddressMode = I2C_DUALADDRESS_DISABLE;
  hi2c3.Init.OwnAddress2 = 0;
  hi2c3.Init.OwnAddress2Masks = I2C_OA2_NOMASK;
  hi2c3.Init.GeneralCallMode = I2C_GENERALCALL_DISABLE;
  hi2c3.Init.NoStretchMode = I2C_NOSTRETCH_DISABLE;
  if (HAL_I2C_Init(&hi2c3) != HAL_OK)
  {
    Error_Handler();
  }

  /** Configure Analogue filter
  */
  if (HAL_I2CEx_ConfigAnalogFilter(&hi2c3, I2C_ANALOGFILTER_ENABLE) != HAL_OK)
  {
    Error_Handler();
  }

  /** Configure Digital filter
  */
  if (HAL_I2CEx_ConfigDigitalFilter(&hi2c3, 0) != HAL_OK)
  {
    Error_Handler();
  }

}

static void MX_I2C4_Init(void)
{

  hi2c4.Instance = I2C4;
  hi2c4.Init.Timing = 0x307075B1;
  hi2c4.Init.OwnAddress1 = 0;
  hi2c4.Init.AddressingMode = I2C_ADDRESSINGMODE_7BIT;
  hi2c4.Init.DualAddressMode = I2C_DUALADDRESS_DISABLE;
  hi2c4.Init.OwnAddress2 = 0;
  hi2c4.Init.OwnAddress2Masks = I2C_OA2_NOMASK;
  hi2c4.Init.GeneralCallMode = I2C_GENERALCALL_DISABLE;
  hi2c4.Init.NoStretchMode = I2C_NOSTRETCH_DISABLE;
  if (HAL_I2C_Init(&hi2c4) != HAL_OK)
  {
    Error_Handler();
  }

  /** Configure Analogue filter
  */
  if (HAL_I2CEx_ConfigAnalogFilter(&hi2c4, I2C_ANALOGFILTER_ENABLE) != HAL_OK)
  {
    Error_Handler();
  }

  /** Configure Digital filter
  */
  if (HAL_I2CEx_ConfigDigitalFilter(&hi2c4, 0) != HAL_OK)
  {
    Error_Handler();
  }

}

static void MX_SPI4_Init(void)
{

  /* SPI4 parameter configuration*/
  hspi4.Instance = SPI4;
  hspi4.Init.Mode = SPI_MODE_MASTER;
  hspi4.Init.Direction = SPI_DIRECTION_2LINES;
  hspi4.Init.DataSize = SPI_DATASIZE_4BIT;
  hspi4.Init.CLKPolarity = SPI_POLARITY_LOW;
  hspi4.Init.CLKPhase = SPI_PHASE_1EDGE;
  hspi4.Init.NSS = SPI_NSS_SOFT;
  hspi4.Init.BaudRatePrescaler = SPI_BAUDRATEPRESCALER_2;
  hspi4.Init.FirstBit = SPI_FIRSTBIT_MSB;
  hspi4.Init.TIMode = SPI_TIMODE_DISABLE;
  hspi4.Init.CRCCalculation = SPI_CRCCALCULATION_DISABLE;
  hspi4.Init.CRCPolynomial = 0x0;
  hspi4.Init.NSSPMode = SPI_NSS_PULSE_ENABLE;
  hspi4.Init.NSSPolarity = SPI_NSS_POLARITY_LOW;
  hspi4.Init.FifoThreshold = SPI_FIFO_THRESHOLD_01DATA;
  hspi4.Init.TxCRCInitializationPattern = SPI_CRC_INITIALIZATION_ALL_ZERO_PATTERN;
  hspi4.Init.RxCRCInitializationPattern = SPI_CRC_INITIALIZATION_ALL_ZERO_PATTERN;
  hspi4.Init.MasterSSIdleness = SPI_MASTER_SS_IDLENESS_00CYCLE;
  hspi4.Init.MasterInterDataIdleness = SPI_MASTER_INTERDATA_IDLENESS_00CYCLE;
  hspi4.Init.MasterReceiverAutoSusp = SPI_MASTER_RX_AUTOSUSP_DISABLE;
  hspi4.Init.MasterKeepIOState = SPI_MASTER_KEEP_IO_STATE_DISABLE;
  hspi4.Init.IOSwap = SPI_IO_SWAP_DISABLE;
  if (HAL_SPI_Init(&hspi4) != HAL_OK)
  {
    Error_Handler();
  }

}

static void MX_TIM1_Init(void)
{

  TIM_Encoder_InitTypeDef sConfig = {0};
  TIM_MasterConfigTypeDef sMasterConfig = {0};

  htim1.Instance = TIM1;
  htim1.Init.Prescaler = 0;
  htim1.Init.CounterMode = TIM_COUNTERMODE_DOWN;
  htim1.Init.Period = 65535;
  htim1.Init.ClockDivision = TIM_CLOCKDIVISION_DIV4;
  htim1.Init.RepetitionCounter = 0;
  htim1.Init.AutoReloadPreload = TIM_AUTORELOAD_PRELOAD_DISABLE;
  sConfig.EncoderMode = TIM_ENCODERMODE_TI12;
  sConfig.IC1Polarity = TIM_ICPOLARITY_FALLING;
  sConfig.IC1Selection = TIM_ICSELECTION_DIRECTTI;
  sConfig.IC1Prescaler = TIM_ICPSC_DIV1;
  sConfig.IC1Filter = 0;
  sConfig.IC2Polarity = TIM_ICPOLARITY_FALLING;
  sConfig.IC2Selection = TIM_ICSELECTION_DIRECTTI;
  sConfig.IC2Prescaler = TIM_ICPSC_DIV1;
  sConfig.IC2Filter = 0;
  if (HAL_TIM_Encoder_Init(&htim1, &sConfig) != HAL_OK)
  {
    Error_Handler();
  }
  sMasterConfig.MasterOutputTrigger = TIM_TRGO_RESET;
  sMasterConfig.MasterOutputTrigger2 = TIM_TRGO2_RESET;
  sMasterConfig.MasterSlaveMode = TIM_MASTERSLAVEMODE_DISABLE;
  if (HAL_TIMEx_MasterConfigSynchronization(&htim1, &sMasterConfig) != HAL_OK)
  {
    Error_Handler();
  }

}

static void MX_TIM2_Init(void)
{

  TIM_Encoder_InitTypeDef sConfig = {0};
  TIM_MasterConfigTypeDef sMasterConfig = {0};

  htim2.Instance = TIM2;
  htim2.Init.Prescaler = 0;
  htim2.Init.CounterMode = TIM_COUNTERMODE_DOWN;
  htim2.Init.Period = 65535;
  htim2.Init.ClockDivision = TIM_CLOCKDIVISION_DIV4;
  htim2.Init.AutoReloadPreload = TIM_AUTORELOAD_PRELOAD_DISABLE;
  sConfig.EncoderMode = TIM_ENCODERMODE_TI12;
  sConfig.IC1Polarity = TIM_ICPOLARITY_FALLING;
  sConfig.IC1Selection = TIM_ICSELECTION_DIRECTTI;
  sConfig.IC1Prescaler = TIM_ICPSC_DIV1;
  sConfig.IC1Filter = 0;
  sConfig.IC2Polarity = TIM_ICPOLARITY_FALLING;
  sConfig.IC2Selection = TIM_ICSELECTION_DIRECTTI;
  sConfig.IC2Prescaler = TIM_ICPSC_DIV1;
  sConfig.IC2Filter = 0;
  if (HAL_TIM_Encoder_Init(&htim2, &sConfig) != HAL_OK)
  {
    Error_Handler();
  }
  sMasterConfig.MasterOutputTrigger = TIM_TRGO_RESET;
  sMasterConfig.MasterSlaveMode = TIM_MASTERSLAVEMODE_DISABLE;
  if (HAL_TIMEx_MasterConfigSynchronization(&htim2, &sMasterConfig) != HAL_OK)
  {
    Error_Handler();
  }

}

static void MX_TIM3_Init(void)
{

  TIM_Encoder_InitTypeDef sConfig = {0};
  TIM_MasterConfigTypeDef sMasterConfig = {0};

  htim3.Instance = TIM3;
  htim3.Init.Prescaler = 0;
  htim3.Init.CounterMode = TIM_COUNTERMODE_DOWN;
  htim3.Init.Period = 65535;
  htim3.Init.ClockDivision = TIM_CLOCKDIVISION_DIV4;
  htim3.Init.AutoReloadPreload = TIM_AUTORELOAD_PRELOAD_DISABLE;
  sConfig.EncoderMode = TIM_ENCODERMODE_TI12;
  sConfig.IC1Polarity = TIM_ICPOLARITY_FALLING;
  sConfig.IC1Selection = TIM_ICSELECTION_DIRECTTI;
  sConfig.IC1Prescaler = TIM_ICPSC_DIV1;
  sConfig.IC1Filter = 0;
  sConfig.IC2Polarity = TIM_ICPOLARITY_FALLING;
  sConfig.IC2Selection = TIM_ICSELECTION_DIRECTTI;
  sConfig.IC2Prescaler = TIM_ICPSC_DIV1;
  sConfig.IC2Filter = 0;
  if (HAL_TIM_Encoder_Init(&htim3, &sConfig) != HAL_OK)
  {
    Error_Handler();
  }
  sMasterConfig.MasterOutputTrigger = TIM_TRGO_RESET;
  sMasterConfig.MasterSlaveMode = TIM_MASTERSLAVEMODE_DISABLE;
  if (HAL_TIMEx_MasterConfigSynchronization(&htim3, &sMasterConfig) != HAL_OK)
  {
    Error_Handler();
  }

}

static void MX_TIM4_Init(void)
{

  TIM_Encoder_InitTypeDef sConfig = {0};
  TIM_MasterConfigTypeDef sMasterConfig = {0};

  htim4.Instance = TIM4;
  htim4.Init.Prescaler = 0;
  htim4.Init.CounterMode = TIM_COUNTERMODE_DOWN;
  htim4.Init.Period = 65535;
  htim4.Init.ClockDivision = TIM_CLOCKDIVISION_DIV4;
  htim4.Init.AutoReloadPreload = TIM_AUTORELOAD_PRELOAD_DISABLE;
  sConfig.EncoderMode = TIM_ENCODERMODE_TI12;
  sConfig.IC1Polarity = TIM_ICPOLARITY_FALLING;
  sConfig.IC1Selection = TIM_ICSELECTION_DIRECTTI;
  sConfig.IC1Prescaler = TIM_ICPSC_DIV1;
  sConfig.IC1Filter = 0;
  sConfig.IC2Polarity = TIM_ICPOLARITY_FALLING;
  sConfig.IC2Selection = TIM_ICSELECTION_DIRECTTI;
  sConfig.IC2Prescaler = TIM_ICPSC_DIV1;
  sConfig.IC2Filter = 0;
  if (HAL_TIM_Encoder_Init(&htim4, &sConfig) != HAL_OK)
  {
    Error_Handler();
  }
  sMasterConfig.MasterOutputTrigger = TIM_TRGO_RESET;
  sMasterConfig.MasterSlaveMode = TIM_MASTERSLAVEMODE_DISABLE;
  if (HAL_TIMEx_MasterConfigSynchronization(&htim4, &sMasterConfig) != HAL_OK)
  {
    Error_Handler();
  }

}

static void MX_TIM5_Init(void)
{

  TIM_Encoder_InitTypeDef sConfig = {0};
  TIM_MasterConfigTypeDef sMasterConfig = {0};

  htim5.Instance = TIM5;
  htim5.Init.Prescaler = 0;
  htim5.Init.CounterMode = TIM_COUNTERMODE_DOWN;
  htim5.Init.Period = 65535;
  htim5.Init.ClockDivision = TIM_CLOCKDIVISION_DIV4;
  htim5.Init.AutoReloadPreload = TIM_AUTORELOAD_PRELOAD_DISABLE;
  sConfig.EncoderMode = TIM_ENCODERMODE_TI12;
  sConfig.IC1Polarity = TIM_ICPOLARITY_FALLING;
  sConfig.IC1Selection = TIM_ICSELECTION_DIRECTTI;
  sConfig.IC1Prescaler = TIM_ICPSC_DIV1;
  sConfig.IC1Filter = 0;
  sConfig.IC2Polarity = TIM_ICPOLARITY_FALLING;
  sConfig.IC2Selection = TIM_ICSELECTION_DIRECTTI;
  sConfig.IC2Prescaler = TIM_ICPSC_DIV1;
  sConfig.IC2Filter = 0;
  if (HAL_TIM_Encoder_Init(&htim5, &sConfig) != HAL_OK)
  {
    Error_Handler();
  }
  sMasterConfig.MasterOutputTrigger = TIM_TRGO_RESET;
  sMasterConfig.MasterSlaveMode = TIM_MASTERSLAVEMODE_DISABLE;
  if (HAL_TIMEx_MasterConfigSynchronization(&htim5, &sMasterConfig) != HAL_OK)
  {
    Error_Handler();
  }

}

static void MX_TIM8_Init(void)
{

  TIM_Encoder_InitTypeDef sConfig = {0};
  TIM_MasterConfigTypeDef sMasterConfig = {0};

  htim8.Instance = TIM8;
  htim8.Init.Prescaler = 0;
  htim8.Init.CounterMode = TIM_COUNTERMODE_DOWN;
  htim8.Init.Period = 65535;
  htim8.Init.ClockDivision = TIM_CLOCKDIVISION_DIV4;
  htim8.Init.RepetitionCounter = 0;
  htim8.Init.AutoReloadPreload = TIM_AUTORELOAD_PRELOAD_DISABLE;
  sConfig.EncoderMode = TIM_ENCODERMODE_TI12;
  sConfig.IC1Polarity = TIM_ICPOLARITY_FALLING;
  sConfig.IC1Selection = TIM_ICSELECTION_DIRECTTI;
  sConfig.IC1Prescaler = TIM_ICPSC_DIV1;
  sConfig.IC1Filter = 0;
  sConfig.IC2Polarity = TIM_ICPOLARITY_FALLING;
  sConfig.IC2Selection = TIM_ICSELECTION_DIRECTTI;
  sConfig.IC2Prescaler = TIM_ICPSC_DIV1;
  sConfig.IC2Filter = 0;
  if (HAL_TIM_Encoder_Init(&htim8, &sConfig) != HAL_OK)
  {
    Error_Handler();
  }
  sMasterConfig.MasterOutputTrigger = TIM_TRGO_RESET;
  sMasterConfig.MasterOutputTrigger2 = TIM_TRGO2_RESET;
  sMasterConfig.MasterSlaveMode = TIM_MASTERSLAVEMODE_DISABLE;
  if (HAL_TIMEx_MasterConfigSynchronization(&htim8, &sMasterConfig) != HAL_OK)
  {
    Error_Handler();
  }

}

static void MX_TIM12_Init(void)
{

  TIM_MasterConfigTypeDef sMasterConfig = {0};
  TIM_OC_InitTypeDef sConfigOC = {0};

  htim12.Instance = TIM12;
  htim12.Init.Prescaler = 0;
  htim12.Init.CounterMode = TIM_COUNTERMODE_UP;
  htim12.Init.Period = 65535;
  htim12.Init.ClockDivision = TIM_CLOCKDIVISION_DIV1;
  htim12.Init.AutoReloadPreload = TIM_AUTORELOAD_PRELOAD_DISABLE;
  if (HAL_TIM_PWM_Init(&htim12) != HAL_OK)
  {
    Error_Handler();
  }
  sMasterConfig.MasterOutputTrigger = TIM_TRGO_RESET;
  sMasterConfig.MasterSlaveMode = TIM_MASTERSLAVEMODE_DISABLE;
  if (HAL_TIMEx_MasterConfigSynchronization(&htim12, &sMasterConfig) != HAL_OK)
  {
    Error_Handler();
  }
  sConfigOC.OCMode = TIM_OCMODE_PWM1;
  sConfigOC.Pulse = 0;
  sConfigOC.OCPolarity = TIM_OCPOLARITY_HIGH;
  sConfigOC.OCFastMode = TIM_OCFAST_DISABLE;
  if (HAL_TIM_PWM_ConfigChannel(&htim12, &sConfigOC, TIM_CHANNEL_1) != HAL_OK)
  {
    Error_Handler();
  }
  HAL_TIM_MspPostInit(&htim12);

}

static void MX_UART4_Init(void)
{

  huart4.Instance = UART4;
  huart4.Init.BaudRate = 115200;
  huart4.Init.WordLength = UART_WORDLENGTH_8B;
  huart4.Init.StopBits = UART_STOPBITS_1;
  huart4.Init.Parity = UART_PARITY_NONE;
  huart4.Init.Mode = UART_MODE_TX_RX;
  huart4.Init.HwFlowCtl = UART_HWCONTROL_NONE;
  huart4.Init.OverSampling = UART_OVERSAMPLING_16;
  huart4.Init.OneBitSampling = UART_ONE_BIT_SAMPLE_DISABLE;
  huart4.Init.ClockPrescaler = UART_PRESCALER_DIV1;
  huart4.AdvancedInit.AdvFeatureInit = UART_ADVFEATURE_NO_INIT;
  if (HAL_UART_Init(&huart4) != HAL_OK)
  {
    Error_Handler();
  }
  if (HAL_UARTEx_SetTxFifoThreshold(&huart4, UART_TXFIFO_THRESHOLD_1_8) != HAL_OK)
  {
    Error_Handler();
  }
  if (HAL_UARTEx_SetRxFifoThreshold(&huart4, UART_RXFIFO_THRESHOLD_1_8) != HAL_OK)
  {
    Error_Handler();
  }
  if (HAL_UARTEx_DisableFifoMode(&huart4) != HAL_OK)
  {
    Error_Handler();
  }

}

static void MX_UART5_Init(void)
{

  huart5.Instance = UART5;
  huart5.Init.BaudRate = 115200;
  huart5.Init.WordLength = UART_WORDLENGTH_8B;
  huart5.Init.StopBits = UART_STOPBITS_1;
  huart5.Init.Parity = UART_PARITY_NONE;
  huart5.Init.Mode = UART_MODE_TX_RX;
  huart5.Init.HwFlowCtl = UART_HWCONTROL_NONE;
  huart5.Init.OverSampling = UART_OVERSAMPLING_16;
  huart5.Init.OneBitSampling = UART_ONE_BIT_SAMPLE_DISABLE;
  huart5.Init.ClockPrescaler = UART_PRESCALER_DIV1;
  huart5.AdvancedInit.AdvFeatureInit = UART_ADVFEATURE_NO_INIT;
  if (HAL_UART_Init(&huart5) != HAL_OK)
  {
    Error_Handler();
  }
  if (HAL_UARTEx_SetTxFifoThreshold(&huart5, UART_TXFIFO_THRESHOLD_1_8) != HAL_OK)
  {
    Error_Handler();
  }
  if (HAL_UARTEx_SetRxFifoThreshold(&huart5, UART_RXFIFO_THRESHOLD_1_8) != HAL_OK)
  {
    Error_Handler();
  }
  if (HAL_UARTEx_DisableFifoMode(&huart5) != HAL_OK)
  {
    Error_Handler();
  }

}

static void MX_UART7_Init(void)
{

  huart7.Instance = UART7;
  huart7.Init.BaudRate = 115200;
  huart7.Init.WordLength = UART_WORDLENGTH_8B;
  huart7.Init.StopBits = UART_STOPBITS_1;
  huart7.Init.Parity = UART_PARITY_NONE;
  huart7.Init.Mode = UART_MODE_TX_RX;
  huart7.Init.HwFlowCtl = UART_HWCONTROL_NONE;
  huart7.Init.OverSampling = UART_OVERSAMPLING_16;
  huart7.Init.OneBitSampling = UART_ONE_BIT_SAMPLE_DISABLE;
  huart7.Init.ClockPrescaler = UART_PRESCALER_DIV1;
  huart7.AdvancedInit.AdvFeatureInit = UART_ADVFEATURE_NO_INIT;
  if (HAL_UART_Init(&huart7) != HAL_OK)
  {
    Error_Handler();
  }
  if (HAL_UARTEx_SetTxFifoThreshold(&huart7, UART_TXFIFO_THRESHOLD_1_8) != HAL_OK)
  {
    Error_Handler();
  }
  if (HAL_UARTEx_SetRxFifoThreshold(&huart7, UART_RXFIFO_THRESHOLD_1_8) != HAL_OK)
  {
    Error_Handler();
  }
  if (HAL_UARTEx_DisableFifoMode(&huart7) != HAL_OK)
  {
    Error_Handler();
  }

}

static void MX_UART8_Init(void)
{

  huart8.Instance = UART8;
  huart8.Init.BaudRate = 115200;
  huart8.Init.WordLength = UART_WORDLENGTH_8B;
  huart8.Init.StopBits = UART_STOPBITS_1;
  huart8.Init.Parity = UART_PARITY_NONE;
  huart8.Init.Mode = UART_MODE_TX_RX;
  huart8.Init.HwFlowCtl = UART_HWCONTROL_NONE;
  huart8.Init.OverSampling = UART_OVERSAMPLING_16;
  huart8.Init.OneBitSampling = UART_ONE_BIT_SAMPLE_DISABLE;
  huart8.Init.ClockPrescaler = UART_PRESCALER_DIV1;
  huart8.AdvancedInit.AdvFeatureInit = UART_ADVFEATURE_NO_INIT;
  if (HAL_UART_Init(&huart8) != HAL_OK)
  {
    Error_Handler();
  }
  if (HAL_UARTEx_SetTxFifoThreshold(&huart8, UART_TXFIFO_THRESHOLD_1_8) != HAL_OK)
  {
    Error_Handler();
  }
  if (HAL_UARTEx_SetRxFifoThreshold(&huart8, UART_RXFIFO_THRESHOLD_1_8) != HAL_OK)
  {
    Error_Handler();
  }
  if (HAL_UARTEx_DisableFifoMode(&huart8) != HAL_OK)
  {
    Error_Handler();
  }

}

static void MX_USART1_UART_Init(void)
{

  huart1.Instance = USART1;
  huart1.Init.BaudRate = 115200;
  huart1.Init.WordLength = UART_WORDLENGTH_8B;
  huart1.Init.StopBits = UART_STOPBITS_1;
  huart1.Init.Parity = UART_PARITY_NONE;
  huart1.Init.Mode = UART_MODE_TX_RX;
  huart1.Init.HwFlowCtl = UART_HWCONTROL_NONE;
  huart1.Init.OverSampling = UART_OVERSAMPLING_16;
  huart1.Init.OneBitSampling = UART_ONE_BIT_SAMPLE_DISABLE;
  huart1.Init.ClockPrescaler = UART_PRESCALER_DIV1;
  huart1.AdvancedInit.AdvFeatureInit = UART_ADVFEATURE_NO_INIT;
  if (HAL_UART_Init(&huart1) != HAL_OK)
  {
    Error_Handler();
  }
  if (HAL_UARTEx_SetTxFifoThreshold(&huart1, UART_TXFIFO_THRESHOLD_1_8) != HAL_OK)
  {
    Error_Handler();
  }
  if (HAL_UARTEx_SetRxFifoThreshold(&huart1, UART_RXFIFO_THRESHOLD_1_8) != HAL_OK)
  {
    Error_Handler();
  }
  if (HAL_UARTEx_DisableFifoMode(&huart1) != HAL_OK)
  {
    Error_Handler();
  }

}

static void MX_USART2_UART_Init(void)
{

  huart2.Instance = USART2;
  huart2.Init.BaudRate = 115200;
  huart2.Init.WordLength = UART_WORDLENGTH_8B;
  huart2.Init.StopBits = UART_STOPBITS_1;
  huart2.Init.Parity = UART_PARITY_NONE;
  huart2.Init.Mode = UART_MODE_TX_RX;
  huart2.Init.HwFlowCtl = UART_HWCONTROL_NONE;
  huart2.Init.OverSampling = UART_OVERSAMPLING_16;
  huart2.Init.OneBitSampling = UART_ONE_BIT_SAMPLE_DISABLE;
  huart2.Init.ClockPrescaler = UART_PRESCALER_DIV1;
  huart2.AdvancedInit.AdvFeatureInit = UART_ADVFEATURE_NO_INIT;
  if (HAL_UART_Init(&huart2) != HAL_OK)
  {
    Error_Handler();
  }
  if (HAL_UARTEx_SetTxFifoThreshold(&huart2, UART_TXFIFO_THRESHOLD_1_8) != HAL_OK)
  {
    Error_Handler();
  }
  if (HAL_UARTEx_SetRxFifoThreshold(&huart2, UART_RXFIFO_THRESHOLD_1_8) != HAL_OK)
  {
    Error_Handler();
  }
  if (HAL_UARTEx_DisableFifoMode(&huart2) != HAL_OK)
  {
    Error_Handler();
  }

}

static void MX_USART3_UART_Init(void)
{

  huart3.Instance = USART3;
  huart3.Init.BaudRate = 115200;
  huart3.Init.WordLength = UART_WORDLENGTH_8B;
  huart3.Init.StopBits = UART_STOPBITS_1;
  huart3.Init.Parity = UART_PARITY_NONE;
  huart3.Init.Mode = UART_MODE_TX_RX;
  huart3.Init.HwFlowCtl = UART_HWCONTROL_NONE;
  huart3.Init.OverSampling = UART_OVERSAMPLING_16;
  huart3.Init.OneBitSampling = UART_ONE_BIT_SAMPLE_DISABLE;
  huart3.Init.ClockPrescaler = UART_PRESCALER_DIV1;
  huart3.AdvancedInit.AdvFeatureInit = UART_ADVFEATURE_NO_INIT;
  if (HAL_UART_Init(&huart3) != HAL_OK)
  {
    Error_Handler();
  }
  if (HAL_UARTEx_SetTxFifoThreshold(&huart3, UART_TXFIFO_THRESHOLD_1_8) != HAL_OK)
  {
    Error_Handler();
  }
  if (HAL_UARTEx_SetRxFifoThreshold(&huart3, UART_RXFIFO_THRESHOLD_1_8) != HAL_OK)
  {
    Error_Handler();
  }
  if (HAL_UARTEx_DisableFifoMode(&huart3) != HAL_OK)
  {
    Error_Handler();
  }

}

static void MX_DMA_Init(void)
{

  /* DMA controller clock enable */
  __HAL_RCC_DMA1_CLK_ENABLE();

  /* DMA interrupt init */
  /* DMA1_Stream2_IRQn interrupt configuration */
  HAL_NVIC_SetPriority(DMA1_Stream2_IRQn, 5, 0);
  HAL_NVIC_EnableIRQ(DMA1_Stream2_IRQn);
  /* DMA1_Stream3_IRQn interrupt configuration */
  HAL_NVIC_SetPriority(DMA1_Stream3_IRQn, 5, 0);
  HAL_NVIC_EnableIRQ(DMA1_Stream3_IRQn);
  /* DMA1_Stream4_IRQn interrupt configuration */
  HAL_NVIC_SetPriority(DMA1_Stream4_IRQn, 5, 0);
  HAL_NVIC_EnableIRQ(DMA1_Stream4_IRQn);

}

static void MX_GPIO_Init(void)
{
  GPIO_InitTypeDef GPIO_InitStruct = {0};

  /* GPIO Ports Clock Enable */
  __HAL_RCC_GPIOE_CLK_ENABLE();
  __HAL_RCC_GPIOC_CLK_ENABLE();
  __HAL_RCC_GPIOH_CLK_ENABLE();
  __HAL_RCC_GPIOA_CLK_ENABLE();
  __HAL_RCC_GPIOB_CLK_ENABLE();
  __HAL_RCC_GPIOD_CLK_ENABLE();

  /*Configure GPIO pin Output Level */
  HAL_GPIO_WritePin(GPIOD, GPIO_PIN_11, GPIO_PIN_RESET);

  /*Configure GPIO pin : PE4 */
  GPIO_InitStruct.Pin = GPIO_PIN_4;
  GPIO_InitStruct.Mode = GPIO_MODE_INPUT;
  GPIO_InitStruct.Pull = GPIO_NOPULL;
  HAL_GPIO_Init(GPIOE, &GPIO_InitStruct);

  /*Configure GPIO pins : PC13 PC14 PC15 PC0
                           PC2 PC3 */
  GPIO_InitStruct.Pin = GPIO_PIN_13|GPIO_PIN_14|GPIO_PIN_15|GPIO_PIN_0
                          |GPIO_PIN_2|GPIO_PIN_3;
  GPIO_InitStruct.Mode = GPIO_MODE_INPUT;
  GPIO_InitStruct.Pull = GPIO_NOPULL;
  HAL_GPIO_Init(GPIOC, &GPIO_InitStruct);

  /*Configure GPIO pin : PD11 */
  GPIO_InitStruct.Pin = GPIO_PIN_11;
  GPIO_InitStruct.Mode = GPIO_MODE_OUTPUT_PP;
  GPIO_InitStruct.Pull = GPIO_NOPULL;
  GPIO_InitStruct.Speed = GPIO_SPEED_FREQ_LOW;
  HAL_GPIO_Init(GPIOD, &GPIO_InitStruct);

  /*Configure GPIO pin : BLUE_RED_Pin */
  GPIO_InitStruct.Pin = BLUE_RED_Pin;
  GPIO_InitStruct.Mode = GPIO_MODE_INPUT;
  GPIO_InitStruct.Pull = GPIO_NOPULL;
  HAL_GPIO_Init(BLUE_RED_GPIO_Port, &GPIO_InitStruct);

}

void StartMainTask(void *argument)
{
  /* USER CODE BEGIN 5 */
  /* Infinite loop */
	HAL_GPIO_TogglePin(GPIOD, GPIO_PIN_11);
  for(;;)
  {
		if(!bit_veHome){
			gamePad();
		}
		//if(UP) ResetEncoder_FULL();
		//mor_1h = 20;
	osDelay(1);
  }
  /* USER CODE END 5 */
}

void StartSensorTask02(void *argument)
{
  /* USER CODE BEGIN StartSensorTask02 */
  /* Infinite loop */

	//run_read_gyro_uart4();	// Khoi tao reset laban
	HAL_UART_Transmit_DMA(&huart1, motorData, sizeof(motorData));		// Mo DMA giao tiep Driver
  for(;;)
  {
		calculateJoystickOutput((int8_t)LJOY_LR, (int8_t)LJOY_UD);
		//sendDataToDriver();
    osDelay(1);
  }
  /* USER CODE END StartSensorTask02 */
}

void StartSwerveTask03(void *argument)
{
  /* USER CODE BEGIN StartSwerveTask03 */
	int bienXoay = 0;
	//PID_Init(&pidRunStraight, 0.5, 0, 0, -250, 250);
  /* Infinite loop */
  for(;;)
  {
		if(bit_veHome) veHome();
		if(!bit_veHome){
			quayGoc3Banh(_0hRO, _4hRO, _8hRO);
			chay3Banh(_0h, _4h, _8h);
		}
//		if(UP) bienXoay = 0;
//		else if(RIGHT) bienXoay = 900;
//		else if(DOWN) bienXoay = 1800;
//		else if(LEFT) bienXoay = 2700;
//		quayGoc0h(bienXoay);
//		quayGoc4h(bienXoay);
//		quayGoc8h(bienXoay);
		////////////////Tat ca DC xoay va dao chieu
//			mor_0hRo = 100;
//			mor_0hRo_next;
//			mor_4hRo = 100;
//			mor_4hRo_next;
//			mor_8hRo = 100;
//			mor_8hRo_next;
//			osDelay(1000);
//
//			mor_0hRo = 100;
//			mor_0hRo_back;
//			mor_4hRo = 100;
//			mor_4hRo_back;
//			mor_8hRo = 100;
//			mor_8hRo_back;
//			osDelay(1000);
////////////////Tat ca DC chay va dao chieu
//			mor_0h = 20;
//			mor_0h_next;
//			mor_4h = 20;
//			mor_4h_next;
//			mor_8h = 20;
//			mor_8h_next;
//			osDelay(1000);
//
//			mor_0h = 20;
//			mor_0h_back;
//			mor_4h = 20;
//			mor_4h_back;
//			mor_8h = 20;
//			mor_8h_back;
//			osDelay(1000);

//		if(UP){
//			mor_0hRo = 100;
//			mor_0hRo_next;
//			mor_4hRo = 100;
//			mor_4hRo_next;
//			mor_8hRo = 100;
//			mor_8hRo_next;
//		}
//		else if(TRIANGLE){
//			mor_0hRo = 100;
//			mor_0hRo_back;
//			mor_4hRo = 100;
//			mor_4hRo_back;
//			mor_8hRo = 100;
//			mor_8hRo_back;
//		}
//		else {
//			mor_0hRo = 2;
//			mor_4hRo = 2;
//			mor_8hRo = 2;
//		}

//		if(LEFT){
//			mor_4hRo = 100;
//			mor_4hRo_next;
//		}
//		else if(SQUARE){
//			mor_4hRo = 100;
//			mor_4hRo_back;
//		}
//		else mor_4hRo = 0;
//
//		if(RIGHT){
//			mor_8hRo = 100;
//			mor_8hRo_next;
//		}
//		else if(O){
//			mor_8hRo = 100;
//			mor_8hRo_back;
//		}
//		else mor_8hRo = 0;
    osDelay(1);
  }
  /* USER CODE END StartSwerveTask03 */
}

void StartADCTask04(void *argument)
{
  /* USER CODE BEGIN StartADCTask04 */
  /* Infinite loop */
  for(;;)
  {
		update_encoder_value();
    osDelay(1);
  }
  /* USER CODE END StartADCTask04 */
}

void StartLCDTask05(void *argument)
{
  /* USER CODE BEGIN StartLCDTask05 */
  /* Infinite loop */

	char modeLCD_Show_Old;
	//CLCD_I2C_Init(&LCD1,&hi2c1,0x4E,20,4); // khoi tao LCD voi ID LCD la 0x4E or 0x7E
	CLCD_I2C_Init(&LCD1,&hi2c1,0x4E,20,4);
	CLCD_I2C_Clear(&LCD1);

  for(;;)
  {
		modeLCD_Show = adc_data[2]/400;
		if(modeLCD_Show != modeLCD_Show_Old)	CLCD_I2C_Clear(&LCD1);

		lcdViewer(modeLCD_Show);
		modeLCD_Show_Old = modeLCD_Show;
    osDelay(1);
  }
  /* USER CODE END StartLCDTask05 */
}

 /* MPU Configuration */

void MPU_Config(void)
{
  MPU_Region_InitTypeDef MPU_InitStruct = {0};

  /* Disables the MPU */
  HAL_MPU_Disable();

  /** Initializes and configures the Region and the memory to be protected
  */
  MPU_InitStruct.Enable = MPU_REGION_ENABLE;
  MPU_InitStruct.Number = MPU_REGION_NUMBER0;
  MPU_InitStruct.BaseAddress = 0x0;
  MPU_InitStruct.Size = MPU_REGION_SIZE_4GB;
  MPU_InitStruct.SubRegionDisable = 0x87;
  MPU_InitStruct.TypeExtField = MPU_TEX_LEVEL0;
  MPU_InitStruct.AccessPermission = MPU_REGION_NO_ACCESS;
  MPU_InitStruct.DisableExec = MPU_INSTRUCTION_ACCESS_DISABLE;
  MPU_InitStruct.IsShareable = MPU_ACCESS_SHAREABLE;
  MPU_InitStruct.IsCacheable = MPU_ACCESS_NOT_CACHEABLE;
  MPU_InitStruct.IsBufferable = MPU_ACCESS_NOT_BUFFERABLE;

  HAL_MPU_ConfigRegion(&MPU_InitStruct);
  /* Enables the MPU */
  HAL_MPU_Enable(MPU_PRIVILEGED_DEFAULT);

}

void HAL_TIM_PeriodElapsedCallback(TIM_HandleTypeDef *htim)
{
  if (htim->Instance == TIM7) {
    HAL_IncTick();
  }
}

void Error_Handler(void)
{
  __disable_irq();
  while (1)
  {
  }
}
